# cyt4dn register map
Vendor: Cypress Semiconductor; Series: cyt4dn; File version: 1.0
CPU: CM7 r0p1, little endian, MPU, FPU, VTOR, 3 interrupt priority bits
Registers are 32-bit, read-write, reset 0x0 unless marked. A register's access mark holds for its fields unless they carry their own. Offsets are from the block's base; [hi:lo] are bit positions; lines under a group give offsets from that group; 'fields as' and 'values as' point back to an identical list.

## VIDEOSS0 (part 15 of 18) — Video and Graphics Subsystem
Base 0x40A00000
0xC0000 FPDLINK0 group — FPD-Link Interface.
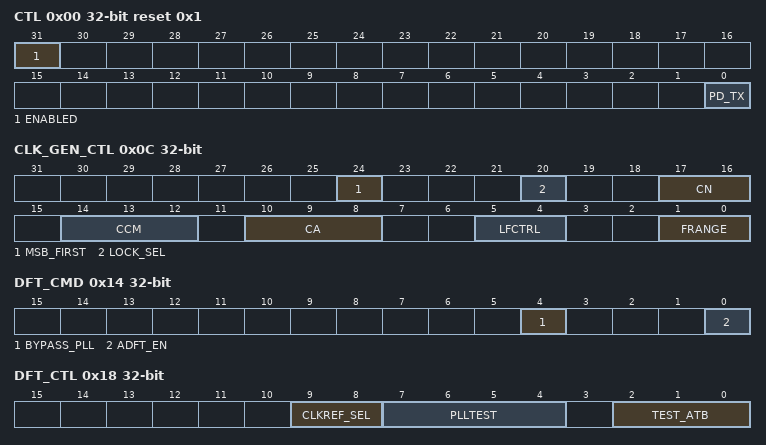
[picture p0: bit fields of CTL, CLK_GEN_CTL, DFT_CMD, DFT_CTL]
  0x00 CTL reset 0x1 — IP Control register for fpdlink
    [31] ENABLED — Enable bit for the FPDLink
      0=DIS (Disable the entire mxvideoss_fpdlink); 1=EN (Enable FPDLink)
    [0] PD_TX — Power down bit, when high all blocks inside the s40efpdlink block shall be powered down
      1=FPDLINK_POWER_DOWN (Power down FPDLINK, this is the default reset value); 0=FPDLINK_POWER_UP (Power up FPDLINK)
  0x04 CMD — IP Command register for fpdlink
    [0] LVDS_TX_EN — Enable the serializers and TX drivers for all lanes of s40efpdlink
      0=FPDLINK_TX_DRIVER_DISABLED (Disable fpdlink TX operation); 1=FPDLINK_TX_DRIVER_ENABLED (Enable fpdlink TX operation)
  0x08 CLK_GEN_CMD — Control register for CLK_GEN
    [0] MODE8 — Enable Dual-Pixel(8-Lane Mode)
      0=MODE4 (4 Lane LVDS mode); 1=MODE8 (8 lane LVDS mode)
  0x0C CLK_GEN_CTL — Configuration register for CKGEN
    [24] MSB_FIRST — Controls parallel to serial transmission order of input 7-bit word
      0=LSB (LSB bit is sent first); 1=MSB (MSB bit is sent first. This is the default value)
    [20] LOCK_SEL — Select internal or external PLL lock
      0=INT (Select Internal Lock. This is the default value); 1=EXT (Select External Lock)
    [17:16] CN — Control N divider used for low bandwidth feature
      0=DIV1 (Default); 1=DIV2 (Lower Bandwidth); 2=DIV4 (Lower Bandwidth); 3=DIV8 (Less than 800khz)
    [14:12] CCM — Common mode voltage control bits.
      2=1P05 (Common mode voltage set to 1.15); 1=1P10 (Common mode voltage set to 1.10); 3=1P20 (Common mode voltage set to 1.20); 4=1P25 (Common mode voltage set to 1.25, this is the default value to be progammed); 5=1P30 (Common mode voltage set to 1.30); 6=1P35 (Common mode voltage set to 1.35); 7=1P40 (Common mode voltage set to 1.40)
    [10:8] CA — Driver output current control bits
      0=2P4MA (Driver output current is 2.4mA); 1=2P72MA (Driver output current is 2.72mA); 2=2P88MA (Driver output current is 2.88mA); 3=3P2MA (Driver output current is 3.2mA); 4=3P36MA (Driver output current is 3.36ma, this is the default value to be progammed); 5=3P68MA (Driver output current is 3.68mA); 6=3P84MA (Driver output current is 3.84mA); 7=4P32MA (Driver output current is 4.32mA)
    [5:4] LFCTRL — Loop filter resistance selection used for low bandwidth feature
      values as CN
    [1:0] FRANGE — Control Output frequency divider, connects to the port CO on the hardIP
      0=DIV1 (Internal PLL output divider programmed to 1); 1=DIV2 (Internal PLL output divider programmed to 2); 2=DIV4 (Internal PLL output divider programmed to 4); 3=DIV8 (Internal PLL output divider programmed to 8)
  0x10 CLK_GEN_STATUS ro — Status register for CKGEN
    [0] PLL_LOCK — Lock Detect output. Asserted when the PLL has achieved frequency lock
  0x14 DFT_CMD — DFT control register for fpdlink
    [4] BYPASS_PLL — BYPASS_PLL, use external clock
      0=BYPASS_DISABLED (CLKOUT is the output of internal PLL); 1=BYPASS_ENABLED (CLKOUT equals CLKEXT)
    [0] ADFT_EN — Enable analog dft (analog test bus)
  0x18 DFT_CTL — DFT configuration register for fpdlink
    [9:8] CLKREF_SEL — Select line of the mux used for selecting reference clock for the internal PLL
      0=SRSSPLL_OUTPUT_W_DIV2 (Output of SRSSPLL, approx 200Mhz, passed through the DIV/2 divider and then used as a reference clock for the PLL); 1=SRSSPLL_INPUT_WO_DIV2 (Use the input clock of the SRSSPLL ,approx 100Mhz, and directly use it as reference clock for the PLL without passing it through the DIV/2 divider); 2=EXT_GPIO (Use external clock from the GPIO ,approx 100Mhz, directly as a reference clock for the PLL); 3=RSVD (N/A)
    [7:4] PLLTEST — PLL Charge Pump current control, connected to port TST of LVDS wrapper
      9=DEFAULT (Default value to be programmed)
    [2:0] TEST_ATB — Analog Test bus select bits used to choose an analog parameter to test
      0=NO_TESTING (Not Testing); 1=BANDGAP_CURRENT (Testing Bandgap Current); 2=COMMON_MODE_VOLTAGE (Testing Common Mode Voltage); 3=CHARGE_PUMP_UP_CURRENT (Testing Charge Pump Up Current); 4=CHARGE_PUMP_DOWN_CURRENT (Testing Charge Pump Down Current); 5=CHARGE_PUMP_MISMATCH_CURRENT (Testing Charge Pump Mismatch Current); 6=LOOP_FILTER_LEAKAGE (Testing Loop Filter Leakage); 7=VCO_VOLTAGE (Testing VCO Voltage)
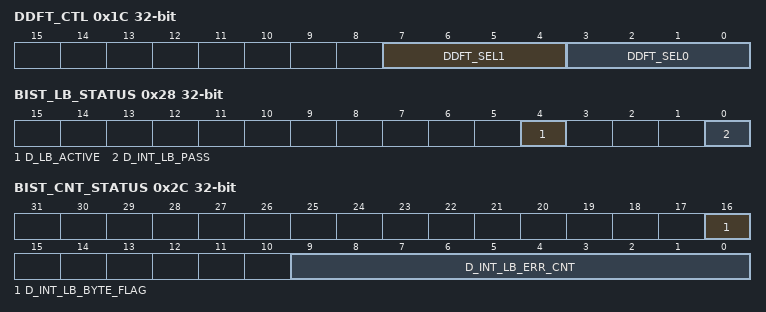
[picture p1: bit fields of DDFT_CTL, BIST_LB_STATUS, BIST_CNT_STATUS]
  0x1C DDFT_CTL — Digital DFT control register (select signals for Muxes used for analog signal checking purposes)
    [7:4] DDFT_SEL1 — Spare DDFT_SEL bits to be used later for analog signal checking
    [3:0] DDFT_SEL0 — Spare DDFT_SEL bits to be used for analog signal checking, by default ddft_out port is kept at constant 0
      0=DEFAULT (By default ddft_out port is kept at constant 0); 1=ROUTE_DDFT_OUT (ROUTE the output ddft_out of the hardIP to the DDFT_OUT port of our wrapper); 2=ROUTE_PLL_LOCK (ROUTE the PLL_LOCK output of the hardIP to the DDFT_OUT port of our wrapper); 3=ROUTE_HS_PXL_CLKS (ROUTE the HS_PXL_CLKS output of the hardIP to the DDFT_OUT port of our wrapper)
  0x20 BIST_CTL — BIST control register
    [4:0] TEST_ENABLE — Enable BIST in the desired conifguration and choose the channle to test
      0=TEST_DISABLED (Functional mode. All tests disabled); 1=CH_A_SER_DES (Channel A TX-serializer is enabled and TX data is looped back to the RX deserializer. The TX serializer sends the test data according to TEST_PATTERN bus. The pattern matcher will receive the HS data and compares it with the programmed TEST_PATTERN bus. The error counter is enabled to check word error rate.); 2=CH_B_SER_DES (This test is the same as TEST_ENBL #00001.Channel B is tested in this test); 3=CH_C_SER_DES (This test is the same as TEST_ENBL #00001.Channel C is tested in this test.); 4=CH_D_SER_DES (This test is the same as TEST_ENBL #00001.Channel D is tested in this test.); 5=CH_CLK_SER_DES (This test is the same as TEST_ENBL #00001.Channel CLK is tested in this test.); 17=CH_A_SER_DES_2PH (Channel A TX-serializer is enabled and TX data is looped back to the RX deserializer. The TX serializer sends the test data according to TEST_PATTERN bus. The pattern matcher will receive the HS data and compares it with the programmed TEST_PATTERN bus. The error counter is enabled to check word error rate.This test will run in a two-phase fashion:Phase1: DESER_POL is set to 1'b0 (Default) Phase2: DESER_POL is set to 1'b1); 18=CH_B_SER_DES_2PH (This test is the same as TEST_ENBL #10001.Channel B is tested in this test.); 19=CH_C_SER_DES_2PH (This test is the same as TEST_ENBL #10001.Channel C is tested in this test.); 20=CH_D_SER_DES_2PH (This test is the same as TEST_ENBL #10001.Channel D is tested in this test.); 21=CH_CLK_SER_DES_2PH (This test is the same as TEST_ENBL #10001.Channel CLK is tested in this test.); 6=CH_A_SER_TX_RX_DES (Channel A TX is enabled, and TX data is looped back from HSTX to HSRX. The TX sends the test data according to TEST_PATTERN bus. The pattern matcher will receive the HS data and compares it with the programmed TEST_PATTERN bus. The error counter is enabled to check word error rate.); 7=CH_B_TX_RX_SER_DES (This test is the same as TEST_ENBL #00110.Channel B is tested in this test.); 8=CH_C_TX_RX_SER_DES (This test is the same as TEST_ENBL #00110.Channel C is tested in this test.); 9=CH_D_TX_RX_SER_DES (This test is the same as TEST_ENBL #00110.Channel D is tested in this test.); 10=CH_CLK_SER_TX_RX_DES (This test is the same as TEST_ENBL #00110.Channel CLK is tested in this test.); 22=CH_A_SER_TX_RX_DES_2PH (Channel A TX is enabled, and TX data is looped back from HSTX to HSRX. The TX sends the test data according to TEST_PATTERN bus. The pattern matcher will receive the HS data and compare it with the programmed TEST_PATTERN bus. The error counter is enabled to check word error rate. This test will run in a two-phase fashion:Phase1: DESER_POL is set to 1'b0 (Default)Phase2: DESER_POL is set to 1'b1); 23=CH_B_SER_TX_RX_DES_2PH (This test is the same as TEST_ENBL #10110.Channel B is tested in this test.); 24=CH_C_SER_TX_RX_DES_2PH (This test is the same as TEST_ENBL #10110.Channel C is tested in this test.); 25=CH_D_SER_TX_RX_DES_2PH (This test is the same as TEST_ENBL #10110.Channel D is tested in this test.); 26=CH_CLK_SER_TX_RX_DES_2PH (This test is the same as TEST_ENBL #10110.Channel CLK is tested in this test.)
  0x24 BIST_DATA — BIST control register
    [27:0] TEST_PATTERN — This is the programmable test pattern used by BIST pattern generator and pattern matcher. The TEST_PATTERN bus value will be used as the payload data during the test. It should be set based on the expected BIST pattern to be sent or received.
  0x28 BIST_LB_STATUS ro — BIST Loopback status register
    [4] D_LB_ACTIVE — Status bit showing that the BIST loopback test is active and running
    [0] D_INT_LB_PASS — Status bit showing the pass/fail result of the test
  0x2C BIST_CNT_STATUS ro — BIST loopback count status register
    [16] D_INT_LB_BYTE_FLAG — Status bit indicating that the LVDS RX received 1024 words and the test is over
    [9:0] D_INT_LB_ERR_CNT — Ten-bit status field that showing the number of failing bytes in case of a test failure.
